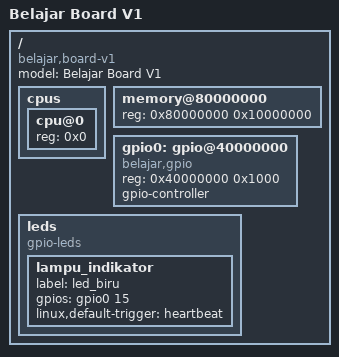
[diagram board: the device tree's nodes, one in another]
/dts-v1/;

/ {
    model = "Belajar Board V1";
    compatible = "belajar,board-v1";

    #address-cells = <1>;
    #size-cells = <1>;

    // Node CPU
    cpus {
        cpu@0 {
            device_type = "cpu";
            reg = <0x0>;
        };
    };

    // Node Memori (RAM)
    memory@80000000 {
        device_type = "memory";
        reg = <0x80000000 0x10000000>;
    };

    // INI NODE BARU: GPIO Controller
    gpio0: gpio@40000000 {
        compatible = "belajar,gpio";
        reg = <0x40000000 0x1000>; // Alamat fiktif GPIO
        
        gpio-controller;           // Wajib ada: Menandakan ini bosnya GPIO
        #gpio-cells = <2>;         // Wajib ada: Format pin (1. Nomor Pin, 2. Status aktif)
    };

    // Node LED
    leds {
        compatible = "gpio-leds";
        
        lampu_indikator {
            label = "led_biru";
            // Sekarang &gpio0 sudah ada, jadi tidak akan error lagi
            gpios = <&gpio0 15 0>; 
            linux,default-trigger = "heartbeat";
        };
    };
};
